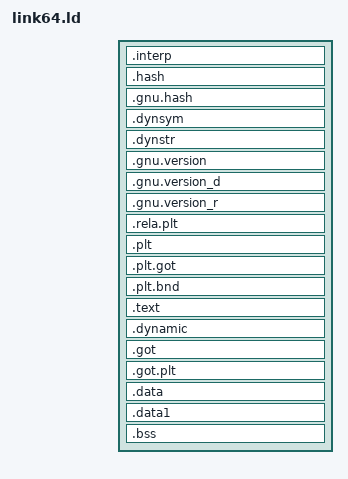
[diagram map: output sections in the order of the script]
/* Script for -z combreloc: combine and sort reloc sections */
/* Copyright (C) 2014-2015 Free Software Foundation, Inc.
   Copying and distribution of this script, with or without modification,
   are permitted in any medium without royalty provided the copyright
   notice and this notice are preserved.  */
OUTPUT_FORMAT("elf64-x86-64", "elf64-x86-64",
	      "elf64-x86-64")
OUTPUT_ARCH(i386:x86-64)
ENTRY(_start)
SEARCH_DIR("=/usr/local/lib/x86_64-linux-gnu"); SEARCH_DIR("=/lib/x86_64-linux-gnu"); SEARCH_DIR("=/usr/lib/x86_64-linux-gnu"); SEARCH_DIR("=/usr/local/lib64"); SEARCH_DIR("=/lib64"); SEARCH_DIR("=/usr/lib64"); SEARCH_DIR("=/usr/local/lib"); SEARCH_DIR("=/lib"); SEARCH_DIR("=/usr/lib"); SEARCH_DIR("=/usr/x86_64-linux-gnu/lib64"); SEARCH_DIR("=/usr/x86_64-linux-gnu/lib");
SECTIONS
{
  /* Read-only sections, merged into text segment: */
  . = SEGMENT_START("text-segment", 0x400000) + SIZEOF_HEADERS;
  .interp         : { *(.interp) }
  .hash           : { *(.hash) }
  .gnu.hash       : { *(.gnu.hash) }
  .dynsym         : { *(.dynsym) }
  .dynstr         : { *(.dynstr) }
  .gnu.version    : { *(.gnu.version) }
  .gnu.version_d  : { *(.gnu.version_d) }
  .gnu.version_r  : { *(.gnu.version_r) }
  .rela.plt       :
    {
      *(.rela.plt)
      PROVIDE_HIDDEN (__rela_iplt_start = .);
      *(.rela.iplt)
      PROVIDE_HIDDEN (__rela_iplt_end = .);
    }
  .plt            : { *(.plt) *(.iplt) }
.plt.got        : { *(.plt.got) }
.plt.bnd        : { *(.plt.bnd) }
  . = ALIGN(16);
  .text           :
  {
    *(.text .text.*)
    *(.rodata .rodata.*)
  }
  . = ALIGN(16);
  .dynamic        : { *(.dynamic) }
  .got            : { *(.got) *(.igot) }
  .got.plt        : { *(.got.plt)  *(.igot.plt) }
  .data           :
  {
    *(.data .data.* .gnu.linkonce.d.*)
    SORT(CONSTRUCTORS)
  }
  .data1          : { *(.data1) }
  . = .;
  .bss            :
  {
   *(.dynbss)
   *(.bss .bss.* .gnu.linkonce.b.*)
   *(COMMON)
   . = ALIGN(. != 0 ? 64 / 8 : 1);
  }
  . = ALIGN(64 / 8);
}



